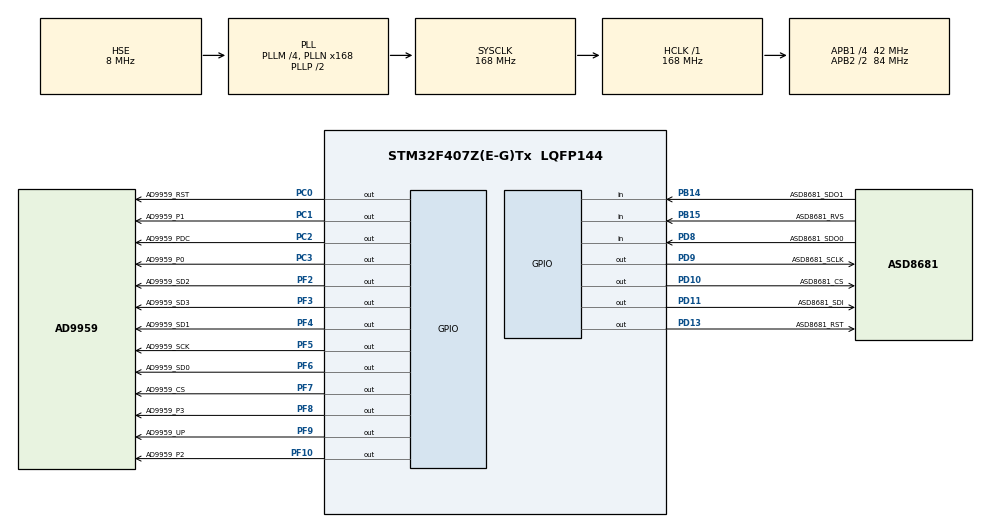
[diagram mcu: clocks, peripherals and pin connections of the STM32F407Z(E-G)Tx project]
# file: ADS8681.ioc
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Mcu.Family=STM32F4
Mcu.Name=STM32F407Z(E-G)Tx
Mcu.Package=LQFP144
NVIC.PriorityGroup=NVIC_PRIORITYGROUP_4
NVIC.TIM2_IRQn=true\:0\:0\:false\:false\:true\:true\:true\:true
NVIC.TIM3_IRQn=true\:0\:0\:false\:false\:true\:true\:true\:true
PA13.Mode=Serial_Wire
PA13.Signal=SYS_JTMS-SWDIO
PA14.Mode=Serial_Wire
PA14.Signal=SYS_JTCK-SWCLK
PB14.GPIO_Label=ASD8681_SDO1
PB14.Signal=GPIO_Input
PB15.GPIO_Label=ASD8681_RVS
PB15.Signal=GPIO_Input
PC0.GPIO_Label=AD9959_RST
PC0.GPIO_Speed=GPIO_SPEED_FREQ_VERY_HIGH
PC0.Signal=GPIO_Output
PC1.GPIO_Label=AD9959_P1
PC1.GPIO_Speed=GPIO_SPEED_FREQ_VERY_HIGH
PC1.Signal=GPIO_Output
PC14-OSC32_IN.Mode=LSE-External-Oscillator
PC14-OSC32_IN.Signal=RCC_OSC32_IN
PC15-OSC32_OUT.Mode=LSE-External-Oscillator
PC15-OSC32_OUT.Signal=RCC_OSC32_OUT
PC2.GPIO_Label=AD9959_PDC
PC2.GPIO_Speed=GPIO_SPEED_FREQ_VERY_HIGH
PC2.Signal=GPIO_Output
PC3.GPIO_Label=AD9959_P0
PC3.GPIO_Speed=GPIO_SPEED_FREQ_VERY_HIGH
PC3.Signal=GPIO_Output
PD10.GPIO_Label=ASD8681_CS
PD10.GPIO_Speed=GPIO_SPEED_FREQ_VERY_HIGH
PD10.Signal=GPIO_Output
PD11.GPIO_Label=ASD8681_SDI
PD11.GPIO_Speed=GPIO_SPEED_FREQ_VERY_HIGH
PD11.Signal=GPIO_Output
PD13.GPIO_Label=ASD8681_RST
PD13.GPIO_Speed=GPIO_SPEED_FREQ_VERY_HIGH
PD13.Signal=GPIO_Output
PD8.GPIO_Label=ASD8681_SDO0
PD8.Signal=GPIO_Input
PD9.GPIO_Label=ASD8681_SCLK
PD9.GPIO_Speed=GPIO_SPEED_FREQ_VERY_HIGH
PD9.Signal=GPIO_Output
PF10.GPIO_Label=AD9959_P2
PF10.GPIO_Speed=GPIO_SPEED_FREQ_VERY_HIGH
PF10.Signal=GPIO_Output
PF2.GPIO_Label=AD9959_SD2
PF2.GPIO_Speed=GPIO_SPEED_FREQ_VERY_HIGH
PF2.Signal=GPIO_Output
PF3.GPIO_Label=AD9959_SD3
PF3.GPIO_Speed=GPIO_SPEED_FREQ_VERY_HIGH
PF3.Signal=GPIO_Output
PF4.GPIO_Label=AD9959_SD1
PF4.GPIO_Speed=GPIO_SPEED_FREQ_VERY_HIGH
PF4.Signal=GPIO_Output
PF5.GPIO_Label=AD9959_SCK
PF5.GPIO_Speed=GPIO_SPEED_FREQ_VERY_HIGH
PF5.Signal=GPIO_Output
PF6.GPIO_Label=AD9959_SD0
PF6.GPIO_Speed=GPIO_SPEED_FREQ_VERY_HIGH
PF6.Signal=GPIO_Output
PF7.GPIO_Label=AD9959_CS
PF7.GPIO_Speed=GPIO_SPEED_FREQ_VERY_HIGH
PF7.Signal=GPIO_Output
PF8.GPIO_Label=AD9959_P3
PF8.GPIO_Speed=GPIO_SPEED_FREQ_VERY_HIGH
PF8.Signal=GPIO_Output
PF9.GPIO_Label=AD9959_UP
PF9.GPIO_Speed=GPIO_SPEED_FREQ_VERY_HIGH
PF9.Signal=GPIO_Output
PH0-OSC_IN.Mode=HSE-External-Oscillator
PH0-OSC_IN.Signal=RCC_OSC_IN
PH1-OSC_OUT.Mode=HSE-External-Oscillator
PH1-OSC_OUT.Signal=RCC_OSC_OUT
ProjectManager.HeapSize=0x200
ProjectManager.StackSize=0x800
ProjectManager.TargetToolchain=STM32CubeIDE
RCC.48MHZClocksFreq_Value=84000000
RCC.AHBFreq_Value=168000000
RCC.APB1CLKDivider=RCC_HCLK_DIV4
RCC.APB1Freq_Value=42000000
RCC.APB1TimFreq_Value=84000000
RCC.APB2CLKDivider=RCC_HCLK_DIV2
RCC.APB2Freq_Value=84000000
RCC.APB2TimFreq_Value=168000000
RCC.CortexFreq_Value=168000000
RCC.HCLKFreq_Value=168000000
RCC.HSE_VALUE=8000000
RCC.HSI_VALUE=16000000
RCC.PLLM=4
RCC.PLLN=168
RCC.PLLSourceVirtual=RCC_PLLSOURCE_HSE
RCC.SYSCLKFreq_VALUE=168000000
RCC.SYSCLKSource=RCC_SYSCLKSOURCE_PLLCLK
RCC.VCOOutputFreq_Value=336000000
TIM2.Channel-Output\ Compare1\ No\ Output=TIM_CHANNEL_1
TIM2.Period=0
TIM2.Prescaler=84-1
TIM2.TIM_MasterOutputTrigger=TIM_TRGO_UPDATE
TIM3.Channel-Output\ Compare1\ No\ Output=TIM_CHANNEL_1
TIM3.Period=1250-1
TIM3.Prescaler=84-1
TIM3.TIM_MasterOutputTrigger=TIM_TRGO_UPDATE
VP_TIM2_VS_ClockSourceINT.Mode=Internal
VP_TIM2_VS_no_output1.Mode=Output Compare1 No Output
VP_TIM3_VS_ClockSourceINT.Mode=Internal
VP_TIM3_VS_no_output1.Mode=Output Compare1 No Output
board=custom

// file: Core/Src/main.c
/* USER CODE BEGIN Header */
/**
  ******************************************************************************
  * @file           : main.c
  * @brief          : Main program body
  ******************************************************************************
  * @attention
  *
  * Copyright (c) 2023 STMicroelectronics.
  * All rights reserved.
  *
  * This software is licensed under terms that can be found in the LICENSE file
  * in the root directory of this software component.
  * If no LICENSE file comes with this software, it is provided AS-IS.
  *
  ******************************************************************************
  */
/* USER CODE END Header */
#include "main.h"
#include "tim.h"
#include "gpio.h"

/* USER CODE BEGIN Includes */
#include "base.h"
#include "ad9959.h"
#include "ads8681.h"
/* USER CODE END Includes */

/* USER CODE BEGIN PV */
uint16_t Rdata = 100;
float Vol = 100;
/* USER CODE END PV */

void SystemClock_Config(void);

int main(void)
{

  /* MCU Configuration--------------------------------------------------------*/

  /* Reset of all peripherals, Initializes the Flash interface and the Systick. */
  HAL_Init();

  /* Configure the system clock */
  SystemClock_Config();

  /* Initialize all configured peripherals */
  MX_GPIO_Init();
  MX_TIM2_Init();
  MX_TIM3_Init();
  /* USER CODE BEGIN 2 */
  Init_AD9959();

  ADS8681_GPIO_Init();			// ADS8681引脚状态初始化
  ADS8681_Init_Mult();			// 初始化时序

  /* USER CODE END 2 */

  /* Infinite loop */
  /* USER CODE BEGIN WHILE */
  while (1)
  {
	  Vol = ADS8681_GetVoltage(Rdata);
	  Rdata = ADS8681_GetData();
    /* USER CODE END WHILE */

  }
}

void SystemClock_Config(void)
{
  RCC_OscInitTypeDef RCC_OscInitStruct = {0};
  RCC_ClkInitTypeDef RCC_ClkInitStruct = {0};

  /** Configure the main internal regulator output voltage
  */
  __HAL_RCC_PWR_CLK_ENABLE();
  __HAL_PWR_VOLTAGESCALING_CONFIG(PWR_REGULATOR_VOLTAGE_SCALE1);

  /** Initializes the RCC Oscillators according to the specified parameters
  * in the RCC_OscInitTypeDef structure.
  */
  RCC_OscInitStruct.OscillatorType = RCC_OSCILLATORTYPE_HSE;
  RCC_OscInitStruct.HSEState = RCC_HSE_ON;
  RCC_OscInitStruct.PLL.PLLState = RCC_PLL_ON;
  RCC_OscInitStruct.PLL.PLLSource = RCC_PLLSOURCE_HSE;
  RCC_OscInitStruct.PLL.PLLM = 4;
  RCC_OscInitStruct.PLL.PLLN = 168;
  RCC_OscInitStruct.PLL.PLLP = RCC_PLLP_DIV2;
  RCC_OscInitStruct.PLL.PLLQ = 4;
  if (HAL_RCC_OscConfig(&RCC_OscInitStruct) != HAL_OK)
  {
    Error_Handler();
  }

  /** Initializes the CPU, AHB and APB buses clocks
  */
  RCC_ClkInitStruct.ClockType = RCC_CLOCKTYPE_HCLK|RCC_CLOCKTYPE_SYSCLK
                              |RCC_CLOCKTYPE_PCLK1|RCC_CLOCKTYPE_PCLK2;
  RCC_ClkInitStruct.SYSCLKSource = RCC_SYSCLKSOURCE_PLLCLK;
  RCC_ClkInitStruct.AHBCLKDivider = RCC_SYSCLK_DIV1;
  RCC_ClkInitStruct.APB1CLKDivider = RCC_HCLK_DIV4;
  RCC_ClkInitStruct.APB2CLKDivider = RCC_HCLK_DIV2;

  if (HAL_RCC_ClockConfig(&RCC_ClkInitStruct, FLASH_LATENCY_5) != HAL_OK)
  {
    Error_Handler();
  }
}

void Error_Handler(void)
{
  __disable_irq();
  while (1)
  {
  }
}
